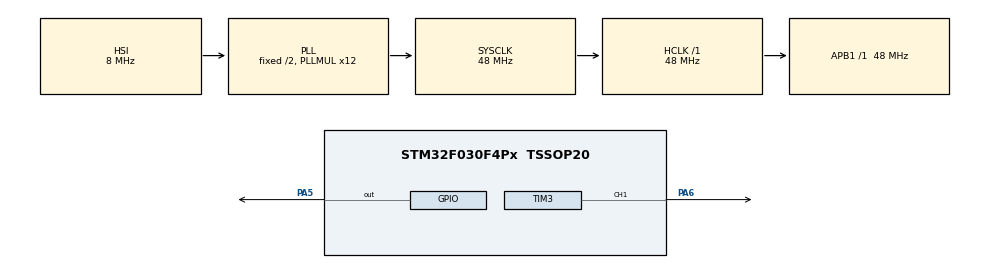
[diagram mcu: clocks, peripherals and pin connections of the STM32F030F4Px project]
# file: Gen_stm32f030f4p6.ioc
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Mcu.Family=STM32F0
Mcu.Name=STM32F030F4Px
Mcu.Package=TSSOP20
NVIC.TIM14_IRQn=true\:0\:0\:false\:false\:true\:true\:true
PA13.Mode=Serial_Wire
PA13.Signal=SYS_SWDIO
PA14.Mode=Serial_Wire
PA14.Signal=SYS_SWCLK
PA5.GPIO_ModeDefaultOutputPP=GPIO_MODE_OUTPUT_PP
PA5.GPIO_PuPd=GPIO_NOPULL
PA5.GPIO_Speed=GPIO_SPEED_FREQ_LOW
PA5.PinState=GPIO_PIN_RESET
PA5.Signal=GPIO_Output
PA6.Signal=S_TIM3_CH1
ProjectManager.HeapSize=0x200
ProjectManager.StackSize=0x400
ProjectManager.TargetToolchain=STM32CubeIDE
RCC.AHBFreq_Value=48000000
RCC.APB1Freq_Value=48000000
RCC.APB1TimFreq_Value=48000000
RCC.HCLKFreq_Value=48000000
RCC.PLLMUL=RCC_PLL_MUL12
RCC.SYSCLKFreq_VALUE=48000000
RCC.SYSCLKSource=RCC_SYSCLKSOURCE_PLLCLK
SH.S_TIM3_CH1.0=TIM3_CH1,Output Compare1 CH1
TIM14.Period=10000-1
TIM14.Prescaler=4800-1
TIM3.AutoReloadPreload=TIM_AUTORELOAD_PRELOAD_ENABLE
TIM3.Channel-Output\ Compare1\ CH1=TIM_CHANNEL_1
TIM3.OC1Preload=ENABLE
TIM3.OCMode_1=TIM_OCMODE_TOGGLE
TIM3.Period=100-1
TIM3.Prescaler=4800-1
TIM3.Pulse-Output\ Compare1\ CH1=10
TIM3.TIM_MasterOutputTrigger=TIM_TRGO_OC1REF
VP_TIM14_VS_ClockSourceINT.Mode=Enable_Timer
VP_TIM3_VS_ClockSourceINT.Mode=Internal
board=custom

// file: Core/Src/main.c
/* USER CODE BEGIN Header */
/**
  ******************************************************************************
  * @file           : main.c
  * @brief          : Main program body
  ******************************************************************************
  * @attention
  *
  * <h2><center>&copy; Copyright (c) 2020 STMicroelectronics.
  * All rights reserved.</center></h2>
  *
  * This software component is licensed by ST under BSD 3-Clause license,
  * the "License"; You may not use this file except in compliance with the
  * License. You may obtain a copy of the License at:
  *                        opensource.org/licenses/BSD-3-Clause
  *
  ******************************************************************************
  */
/* USER CODE END Header */

#include "main.h"

TIM_HandleTypeDef htim3;
TIM_HandleTypeDef htim14;

void SystemClock_Config(void);
static void MX_GPIO_Init(void);
static void MX_TIM14_Init(void);
static void MX_TIM3_Init(void);

int main(void)
{

  /* MCU Configuration--------------------------------------------------------*/

  /* Reset of all peripherals, Initializes the Flash interface and the Systick. */
  HAL_Init();

  /* Configure the system clock */
  SystemClock_Config();

  /* Initialize all configured peripherals */
  MX_GPIO_Init();
  MX_TIM14_Init();
  MX_TIM3_Init();
  /* USER CODE BEGIN 2 */
if(HAL_TIM_OC_Start( &htim3,  TIM_CHANNEL_1)!= HAL_OK)
  {
    /* Starting Error */
    Error_Handler();
  }

  if (HAL_TIM_Base_Start_IT(&htim14) != HAL_OK)
  {
    /* Starting Error */
    Error_Handler();
  }

  /* USER CODE END 2 */

  /* Infinite loop */
  while (1)
  {

  }
}

void SystemClock_Config(void)
{
  RCC_OscInitTypeDef RCC_OscInitStruct = {0};
  RCC_ClkInitTypeDef RCC_ClkInitStruct = {0};

  /** Initializes the CPU, AHB and APB busses clocks
  */
  RCC_OscInitStruct.OscillatorType = RCC_OSCILLATORTYPE_HSI;
  RCC_OscInitStruct.HSIState = RCC_HSI_ON;
  RCC_OscInitStruct.HSICalibrationValue = RCC_HSICALIBRATION_DEFAULT;
  RCC_OscInitStruct.PLL.PLLState = RCC_PLL_ON;
  RCC_OscInitStruct.PLL.PLLSource = RCC_PLLSOURCE_HSI;
  RCC_OscInitStruct.PLL.PLLMUL = RCC_PLL_MUL12;
  RCC_OscInitStruct.PLL.PREDIV = RCC_PREDIV_DIV1;
  if (HAL_RCC_OscConfig(&RCC_OscInitStruct) != HAL_OK)
  {
    Error_Handler();
  }
  /** Initializes the CPU, AHB and APB busses clocks
  */
  RCC_ClkInitStruct.ClockType = RCC_CLOCKTYPE_HCLK|RCC_CLOCKTYPE_SYSCLK
                              |RCC_CLOCKTYPE_PCLK1;
  RCC_ClkInitStruct.SYSCLKSource = RCC_SYSCLKSOURCE_PLLCLK;
  RCC_ClkInitStruct.AHBCLKDivider = RCC_SYSCLK_DIV1;
  RCC_ClkInitStruct.APB1CLKDivider = RCC_HCLK_DIV1;

  if (HAL_RCC_ClockConfig(&RCC_ClkInitStruct, FLASH_LATENCY_1) != HAL_OK)
  {
    Error_Handler();
  }
}

static void MX_TIM3_Init(void)
{

  TIM_ClockConfigTypeDef sClockSourceConfig = {0};
  TIM_MasterConfigTypeDef sMasterConfig = {0};
  TIM_OC_InitTypeDef sConfigOC = {0};

  htim3.Instance = TIM3;
  htim3.Init.Prescaler = 480-1;
  htim3.Init.CounterMode = TIM_COUNTERMODE_UP;
  htim3.Init.Period = 100-1;
  htim3.Init.ClockDivision = TIM_CLOCKDIVISION_DIV1;
  htim3.Init.AutoReloadPreload = TIM_AUTORELOAD_PRELOAD_ENABLE;
  if (HAL_TIM_Base_Init(&htim3) != HAL_OK)
  {
    Error_Handler();
  }
  sClockSourceConfig.ClockSource = TIM_CLOCKSOURCE_INTERNAL;
  if (HAL_TIM_ConfigClockSource(&htim3, &sClockSourceConfig) != HAL_OK)
  {
    Error_Handler();
  }
  if (HAL_TIM_OC_Init(&htim3) != HAL_OK)
  {
    Error_Handler();
  }
  sMasterConfig.MasterOutputTrigger = TIM_TRGO_OC1REF;
  sMasterConfig.MasterSlaveMode = TIM_MASTERSLAVEMODE_DISABLE;
  if (HAL_TIMEx_MasterConfigSynchronization(&htim3, &sMasterConfig) != HAL_OK)
  {
    Error_Handler();
  }
  sConfigOC.OCMode = TIM_OCMODE_TOGGLE;
  sConfigOC.Pulse = 1;
  sConfigOC.OCPolarity = TIM_OCPOLARITY_HIGH;
  sConfigOC.OCFastMode = TIM_OCFAST_DISABLE;
  if (HAL_TIM_OC_ConfigChannel(&htim3, &sConfigOC, TIM_CHANNEL_1) != HAL_OK)
  {
    Error_Handler();
  }
  __HAL_TIM_ENABLE_OCxPRELOAD(&htim3, TIM_CHANNEL_1);
  HAL_TIM_MspPostInit(&htim3);

}

static void MX_TIM14_Init(void)
{

  htim14.Instance = TIM14;
  htim14.Init.Prescaler = 4800-1;
  htim14.Init.CounterMode = TIM_COUNTERMODE_UP;
  htim14.Init.Period = 10000-1;
  htim14.Init.ClockDivision = TIM_CLOCKDIVISION_DIV1;
  htim14.Init.AutoReloadPreload = TIM_AUTORELOAD_PRELOAD_DISABLE;
  if (HAL_TIM_Base_Init(&htim14) != HAL_OK)
  {
    Error_Handler();
  }

}

static void MX_GPIO_Init(void)
{
  GPIO_InitTypeDef GPIO_InitStruct = {0};

  /* GPIO Ports Clock Enable */
  __HAL_RCC_GPIOA_CLK_ENABLE();

  /*Configure GPIO pin Output Level */
  HAL_GPIO_WritePin(GPIOA, GPIO_PIN_5, GPIO_PIN_RESET);

  /*Configure GPIO pin : PA5 */
  GPIO_InitStruct.Pin = GPIO_PIN_5;
  GPIO_InitStruct.Mode = GPIO_MODE_OUTPUT_PP;
  GPIO_InitStruct.Pull = GPIO_NOPULL;
  GPIO_InitStruct.Speed = GPIO_SPEED_FREQ_LOW;
  HAL_GPIO_Init(GPIOA, &GPIO_InitStruct);

}

void Error_Handler(void)
{
}

/************************ (C) COPYRIGHT STMicroelectronics *****END OF FILE****/
